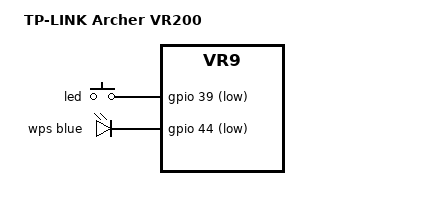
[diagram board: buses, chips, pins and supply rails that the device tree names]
#include <dt-bindings/leds/common.h>

#include "vr9_tplink_vr200.dtsi"

/ {
	compatible = "tplink,vr200", "lantiq,xway", "lantiq,vr9";
	model = "TP-LINK Archer VR200";

	chosen {
		bootargs = "console=ttyLTQ0,115200";
	};
};

&keys {
	led {
		label = "led";
		gpios = <&gpio 39 GPIO_ACTIVE_LOW>;
		linux,code = <KEY_LIGHTS_TOGGLE>;
	};
};

&leds {
	wps {
		function = LED_FUNCTION_WPS;
		color = <LED_COLOR_ID_BLUE>;
		gpios = <&gpio 44 GPIO_ACTIVE_LOW>;
	};
};
